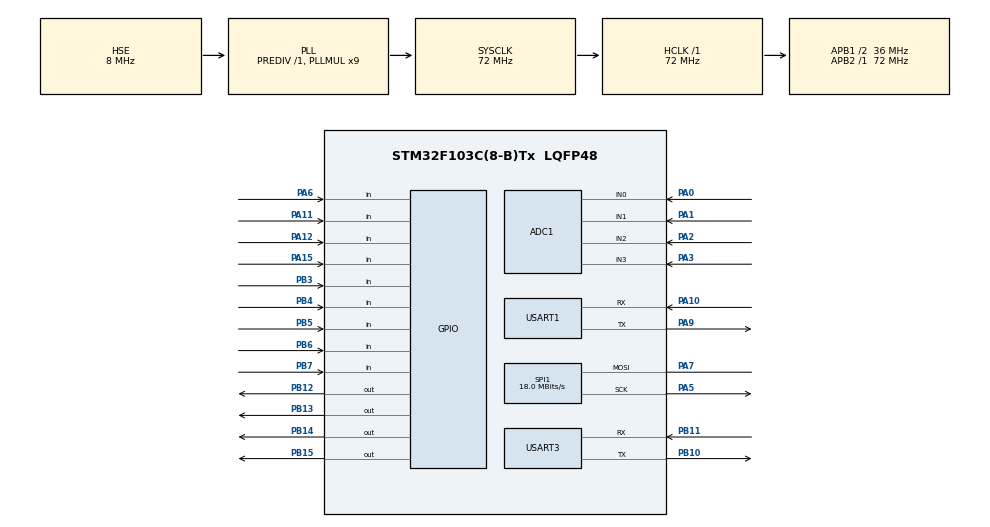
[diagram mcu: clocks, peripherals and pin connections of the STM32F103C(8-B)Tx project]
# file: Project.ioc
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ADC1.Channel-0\#ChannelRegularConversion=ADC_CHANNEL_0
ADC1.DataAlign=ADC_DATAALIGN_RIGHT
ADC1.NbrOfConversion=1
ADC1.NbrOfConversionFlag=1
ADC1.Rank-0\#ChannelRegularConversion=1
ADC1.SamplingTime-0\#ChannelRegularConversion=ADC_SAMPLETIME_1CYCLE_5
ADC1.master=1
Dma.Request0=USART3_RX
Dma.Request1=USART1_RX
Dma.Request2=USART3_TX
Dma.Request3=USART1_TX
Dma.USART1_RX.1.Direction=DMA_PERIPH_TO_MEMORY
Dma.USART1_RX.1.Instance=DMA1_Channel5
Dma.USART1_RX.1.MemDataAlignment=DMA_MDATAALIGN_BYTE
Dma.USART1_RX.1.MemInc=DMA_MINC_ENABLE
Dma.USART1_RX.1.Mode=DMA_NORMAL
Dma.USART1_RX.1.PeriphDataAlignment=DMA_PDATAALIGN_BYTE
Dma.USART1_RX.1.PeriphInc=DMA_PINC_DISABLE
Dma.USART1_RX.1.Priority=DMA_PRIORITY_LOW
Dma.USART1_TX.3.Direction=DMA_MEMORY_TO_PERIPH
Dma.USART1_TX.3.Instance=DMA1_Channel4
Dma.USART1_TX.3.MemDataAlignment=DMA_MDATAALIGN_BYTE
Dma.USART1_TX.3.MemInc=DMA_MINC_ENABLE
Dma.USART1_TX.3.Mode=DMA_NORMAL
Dma.USART1_TX.3.PeriphDataAlignment=DMA_PDATAALIGN_BYTE
Dma.USART1_TX.3.PeriphInc=DMA_PINC_DISABLE
Dma.USART1_TX.3.Priority=DMA_PRIORITY_LOW
Dma.USART3_RX.0.Direction=DMA_PERIPH_TO_MEMORY
Dma.USART3_RX.0.Instance=DMA1_Channel3
Dma.USART3_RX.0.MemDataAlignment=DMA_MDATAALIGN_BYTE
Dma.USART3_RX.0.MemInc=DMA_MINC_ENABLE
Dma.USART3_RX.0.Mode=DMA_NORMAL
Dma.USART3_RX.0.PeriphDataAlignment=DMA_PDATAALIGN_BYTE
Dma.USART3_RX.0.PeriphInc=DMA_PINC_DISABLE
Dma.USART3_RX.0.Priority=DMA_PRIORITY_LOW
Dma.USART3_TX.2.Direction=DMA_MEMORY_TO_PERIPH
Dma.USART3_TX.2.Instance=DMA1_Channel2
Dma.USART3_TX.2.MemDataAlignment=DMA_MDATAALIGN_BYTE
Dma.USART3_TX.2.MemInc=DMA_MINC_ENABLE
Dma.USART3_TX.2.Mode=DMA_NORMAL
Dma.USART3_TX.2.PeriphDataAlignment=DMA_PDATAALIGN_BYTE
Dma.USART3_TX.2.PeriphInc=DMA_PINC_DISABLE
Dma.USART3_TX.2.Priority=DMA_PRIORITY_LOW
Mcu.Family=STM32F1
Mcu.Name=STM32F103C(8-B)Tx
Mcu.Package=LQFP48
NVIC.DMA1_Channel2_IRQn=true\:0\:0\:false\:false\:true\:false\:true\:true
NVIC.DMA1_Channel3_IRQn=true\:0\:0\:false\:false\:true\:false\:true\:true
NVIC.DMA1_Channel4_IRQn=true\:0\:0\:false\:false\:true\:false\:true\:true
NVIC.DMA1_Channel5_IRQn=true\:0\:0\:false\:false\:true\:false\:true\:true
NVIC.PriorityGroup=NVIC_PRIORITYGROUP_4
NVIC.USART1_IRQn=true\:0\:0\:false\:false\:true\:true\:true\:true
NVIC.USART3_IRQn=true\:0\:0\:false\:false\:true\:true\:true\:true
PA0-WKUP.Signal=ADCx_IN0
PA1.Signal=ADCx_IN1
PA10.Mode=Asynchronous
PA10.Signal=USART1_RX
PA11.GPIO_PuPd=GPIO_PULLUP
PA11.Signal=GPIO_Input
PA12.GPIO_PuPd=GPIO_PULLUP
PA12.Signal=GPIO_Input
PA13.Mode=Serial_Wire
PA13.Signal=SYS_JTMS-SWDIO
PA14.Mode=Serial_Wire
PA14.Signal=SYS_JTCK-SWCLK
PA15.GPIO_PuPd=GPIO_PULLUP
PA15.Signal=GPIO_Input
PA2.Signal=ADCx_IN2
PA3.Signal=ADCx_IN3
PA5.Mode=Simplex_Bidirectional_Master
PA5.Signal=SPI1_SCK
PA6.GPIO_PuPd=GPIO_PULLUP
PA6.Signal=GPIO_Input
PA7.Mode=Simplex_Bidirectional_Master
PA7.Signal=SPI1_MOSI
PA9.Mode=Asynchronous
PA9.Signal=USART1_TX
PB10.Mode=Asynchronous
PB10.Signal=USART3_TX
PB11.Mode=Asynchronous
PB11.Signal=USART3_RX
PB12.Signal=GPIO_Output
PB13.Signal=GPIO_Output
PB14.PinState=GPIO_PIN_RESET
PB14.Signal=GPIO_Output
PB15.Signal=GPIO_Output
PB3.GPIO_PuPd=GPIO_PULLUP
PB3.Signal=GPIO_Input
PB4.GPIO_PuPd=GPIO_PULLUP
PB4.Signal=GPIO_Input
PB5.GPIO_PuPd=GPIO_PULLUP
PB5.Signal=GPIO_Input
PB6.GPIO_PuPd=GPIO_PULLUP
PB6.Signal=GPIO_Input
PB7.GPIO_PuPd=GPIO_PULLUP
PB7.Signal=GPIO_Input
PD0-OSC_IN.Mode=HSE-External-Oscillator
PD0-OSC_IN.Signal=RCC_OSC_IN
PD1-OSC_OUT.Mode=HSE-External-Oscillator
PD1-OSC_OUT.Signal=RCC_OSC_OUT
ProjectManager.HeapSize=0x200
ProjectManager.StackSize=0x400
ProjectManager.TargetToolchain=MDK-ARM V5.32
RCC.ADCPresc=RCC_ADCPCLK2_DIV6
RCC.AHBFreq_Value=72000000
RCC.APB1CLKDivider=RCC_HCLK_DIV2
RCC.APB1Freq_Value=36000000
RCC.APB1TimFreq_Value=72000000
RCC.APB2Freq_Value=72000000
RCC.APB2TimFreq_Value=72000000
RCC.HCLKFreq_Value=72000000
RCC.PLLMUL=RCC_PLL_MUL9
RCC.PLLSourceVirtual=RCC_PLLSOURCE_HSE
RCC.SYSCLKFreq_VALUE=72000000
RCC.SYSCLKSource=RCC_SYSCLKSOURCE_PLLCLK
RCC.USBFreq_Value=72000000
SH.ADCx_IN0.0=ADC2_IN0
SH.ADCx_IN0.1=ADC1_IN0,IN0
SH.ADCx_IN1.0=ADC1_IN1,IN1
SH.ADCx_IN1.1=ADC2_IN1
SH.ADCx_IN2.0=ADC1_IN2,IN2
SH.ADCx_IN2.1=ADC2_IN2
SH.ADCx_IN3.0=ADC1_IN3,IN3
SPI1.BaudRatePrescaler=SPI_BAUDRATEPRESCALER_4
SPI1.CalculateBaudRate=18.0 MBits/s
SPI1.Direction=SPI_DIRECTION_1LINE
SPI1.Mode=SPI_MODE_MASTER
SPI1.VirtualType=VM_MASTER
USART1.VirtualMode=VM_ASYNC
USART3.VirtualMode=VM_ASYNC
board=custom

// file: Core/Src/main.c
/* USER CODE BEGIN Header */
/**
  ******************************************************************************
  * @file           : main.c
  * @brief          : Main program body
  ******************************************************************************
  * @attention
  *
  * Copyright (c) 2025 STMicroelectronics.
  * All rights reserved.
  *
  * This software is licensed under terms that can be found in the LICENSE file
  * in the root directory of this software component.
  * If no LICENSE file comes with this software, it is provided AS-IS.
  *
  ******************************************************************************
  */
/* USER CODE END Header */
#include "main.h"
#include "adc.h"
#include "dma.h"
#include "spi.h"
#include "usart.h"
#include "gpio.h"

/* USER CODE BEGIN Includes */
//#include "st7789.h"

//#include "delay.h"
//#include "st7789.h"
//#include "pic.h"

#include "lcd_bsp.h"

/* USER CODE END Includes */

void SystemClock_Config(void);

int main(void)
{

  /* MCU Configuration--------------------------------------------------------*/

  /* Reset of all peripherals, Initializes the Flash interface and the Systick. */
  HAL_Init();

  /* Configure the system clock */
  SystemClock_Config();

  /* Initialize all configured peripherals */
  MX_GPIO_Init();
  MX_DMA_Init();
  MX_USART3_UART_Init();
  MX_ADC1_Init();
  MX_USART1_UART_Init();
  MX_SPI1_Init();

  /* Infinite loop */
  /* USER CODE BEGIN WHILE */

  HAL_GPIO_WritePin(GPIOB, GPIO_PIN_14, GPIO_PIN_RESET);

//	DWT_Delay_Init();
//	LCD_Init( );
//    HAL_Delay(100);
//	LCD_Fill(0,0,LCD_W,LCD_H,WHITE);

  ST7789_Init(WHITE,RED);
  ST7789_Clear(WHITE);
	POINT_COLOR = RED;

  while (1)
  {

      ST7789_Clear(RED);
//		LCD_ShowChinese(0,0,"�о�԰����",RED,WHITE,32,0);
//		LCD_ShowString(0,40,"LCD_W:",RED,WHITE,16,0);
//		LCD_ShowIntNum(48,40,LCD_W,3,RED,WHITE,16);
//		LCD_ShowString(80,40,"LCD_H:",RED,WHITE,16,0);
//		LCD_ShowIntNum(128,40,LCD_H,3,RED,WHITE,16);
//		LCD_ShowString(80,40,"LCD_H:",RED,WHITE,16,0);
//		LCD_ShowString(0,70,"Increaseing Nun:",RED,WHITE,16,0);

    /* USER CODE END WHILE */

  }
}

void SystemClock_Config(void)
{
  RCC_OscInitTypeDef RCC_OscInitStruct = {0};
  RCC_ClkInitTypeDef RCC_ClkInitStruct = {0};
  RCC_PeriphCLKInitTypeDef PeriphClkInit = {0};

  /** Initializes the RCC Oscillators according to the specified parameters
  * in the RCC_OscInitTypeDef structure.
  */
  RCC_OscInitStruct.OscillatorType = RCC_OSCILLATORTYPE_HSE;
  RCC_OscInitStruct.HSEState = RCC_HSE_ON;
  RCC_OscInitStruct.HSEPredivValue = RCC_HSE_PREDIV_DIV1;
  RCC_OscInitStruct.HSIState = RCC_HSI_ON;
  RCC_OscInitStruct.PLL.PLLState = RCC_PLL_ON;
  RCC_OscInitStruct.PLL.PLLSource = RCC_PLLSOURCE_HSE;
  RCC_OscInitStruct.PLL.PLLMUL = RCC_PLL_MUL9;
  if (HAL_RCC_OscConfig(&RCC_OscInitStruct) != HAL_OK)
  {
    Error_Handler();
  }

  /** Initializes the CPU, AHB and APB buses clocks
  */
  RCC_ClkInitStruct.ClockType = RCC_CLOCKTYPE_HCLK|RCC_CLOCKTYPE_SYSCLK
                              |RCC_CLOCKTYPE_PCLK1|RCC_CLOCKTYPE_PCLK2;
  RCC_ClkInitStruct.SYSCLKSource = RCC_SYSCLKSOURCE_PLLCLK;
  RCC_ClkInitStruct.AHBCLKDivider = RCC_SYSCLK_DIV1;
  RCC_ClkInitStruct.APB1CLKDivider = RCC_HCLK_DIV2;
  RCC_ClkInitStruct.APB2CLKDivider = RCC_HCLK_DIV1;

  if (HAL_RCC_ClockConfig(&RCC_ClkInitStruct, FLASH_LATENCY_2) != HAL_OK)
  {
    Error_Handler();
  }
  PeriphClkInit.PeriphClockSelection = RCC_PERIPHCLK_ADC;
  PeriphClkInit.AdcClockSelection = RCC_ADCPCLK2_DIV6;
  if (HAL_RCCEx_PeriphCLKConfig(&PeriphClkInit) != HAL_OK)
  {
    Error_Handler();
  }
}

void Error_Handler(void)
{
  __disable_irq();
  while (1)
  {
  }
}
